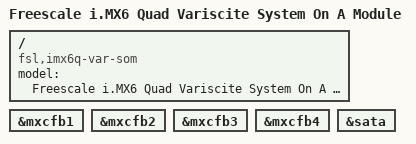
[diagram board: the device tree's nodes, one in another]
/*
 * Copyright (C) 2014 Variscite, Ltd. All Rights Reserved
 * Donio Ron: ron.d@variscite.com
 *
 * Copyright 2012 Freescale Semiconductor, Inc.
 * Copyright 2011 Linaro Ltd.
 *
 * The code contained herein is licensed under the GNU General Public
 * License. You may obtain a copy of the GNU General Public License
 * Version 2 or later at the following locations:
 *
 * http://www.opensource.org/licenses/gpl-license.html
 * http://www.gnu.org/copyleft/gpl.html
 */

/dts-v1/;

#include "imx6q.dtsi"
#include "imx6qdl-var-som.dtsi"

/ {
	model = "Freescale i.MX6 Quad Variscite System On A Module";
	compatible = "fsl,imx6q-var-som", "fsl,imx6q";
};

&mxcfb1 {
	status = "okay";
};

&mxcfb2 {
	status = "okay";
};

&mxcfb3 {
	status = "okay";
};

&mxcfb4 {
	status = "okay";
};

&sata {
	status = "okay";
};
